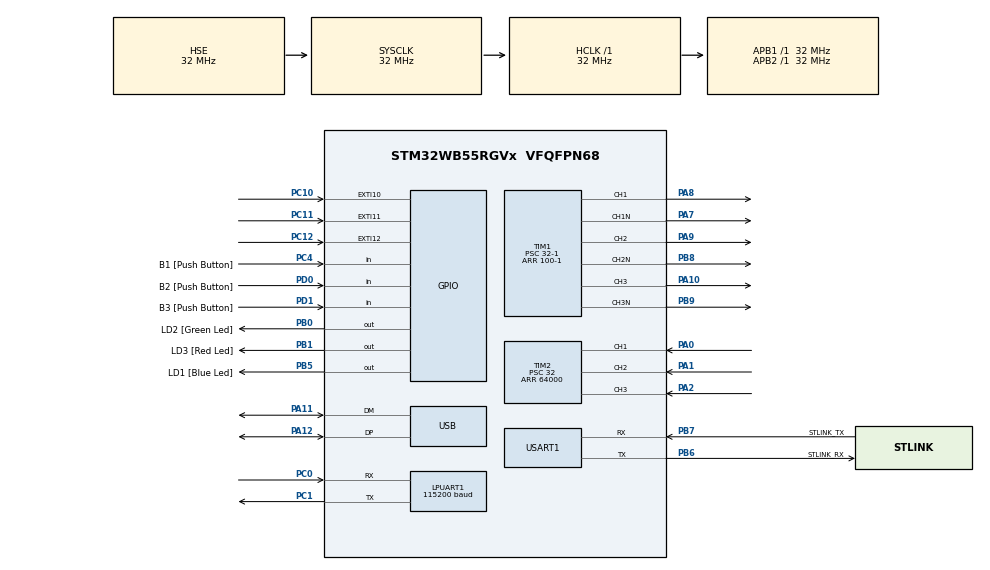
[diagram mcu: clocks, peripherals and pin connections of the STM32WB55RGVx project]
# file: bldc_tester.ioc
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Dma.Request0=TIM1_CH1
Dma.Request1=TIM1_CH2
Dma.Request2=TIM1_CH3
Dma.TIM1_CH1.0.Direction=DMA_PERIPH_TO_MEMORY
Dma.TIM1_CH1.0.EventEnable=DISABLE
Dma.TIM1_CH1.0.Instance=DMA1_Channel1
Dma.TIM1_CH1.0.MemDataAlignment=DMA_MDATAALIGN_HALFWORD
Dma.TIM1_CH1.0.MemInc=DMA_MINC_ENABLE
Dma.TIM1_CH1.0.Mode=DMA_NORMAL
Dma.TIM1_CH1.0.PeriphDataAlignment=DMA_PDATAALIGN_HALFWORD
Dma.TIM1_CH1.0.PeriphInc=DMA_PINC_DISABLE
Dma.TIM1_CH1.0.Polarity=HAL_DMAMUX_REQ_GEN_RISING
Dma.TIM1_CH1.0.Priority=DMA_PRIORITY_LOW
Dma.TIM1_CH1.0.RequestNumber=1
Dma.TIM1_CH1.0.SignalID=NONE
Dma.TIM1_CH1.0.SyncEnable=DISABLE
Dma.TIM1_CH1.0.SyncPolarity=HAL_DMAMUX_SYNC_NO_EVENT
Dma.TIM1_CH1.0.SyncRequestNumber=1
Dma.TIM1_CH1.0.SyncSignalID=NONE
Dma.TIM1_CH2.1.Direction=DMA_PERIPH_TO_MEMORY
Dma.TIM1_CH2.1.EventEnable=DISABLE
Dma.TIM1_CH2.1.Instance=DMA1_Channel2
Dma.TIM1_CH2.1.MemDataAlignment=DMA_MDATAALIGN_HALFWORD
Dma.TIM1_CH2.1.MemInc=DMA_MINC_ENABLE
Dma.TIM1_CH2.1.Mode=DMA_NORMAL
Dma.TIM1_CH2.1.PeriphDataAlignment=DMA_PDATAALIGN_HALFWORD
Dma.TIM1_CH2.1.PeriphInc=DMA_PINC_DISABLE
Dma.TIM1_CH2.1.Polarity=HAL_DMAMUX_REQ_GEN_RISING
Dma.TIM1_CH2.1.Priority=DMA_PRIORITY_LOW
Dma.TIM1_CH2.1.RequestNumber=1
Dma.TIM1_CH2.1.SignalID=NONE
Dma.TIM1_CH2.1.SyncEnable=DISABLE
Dma.TIM1_CH2.1.SyncPolarity=HAL_DMAMUX_SYNC_NO_EVENT
Dma.TIM1_CH2.1.SyncRequestNumber=1
Dma.TIM1_CH2.1.SyncSignalID=NONE
Dma.TIM1_CH3.2.Direction=DMA_PERIPH_TO_MEMORY
Dma.TIM1_CH3.2.EventEnable=DISABLE
Dma.TIM1_CH3.2.Instance=DMA1_Channel3
Dma.TIM1_CH3.2.MemDataAlignment=DMA_MDATAALIGN_HALFWORD
Dma.TIM1_CH3.2.MemInc=DMA_MINC_ENABLE
Dma.TIM1_CH3.2.Mode=DMA_NORMAL
Dma.TIM1_CH3.2.PeriphDataAlignment=DMA_PDATAALIGN_HALFWORD
Dma.TIM1_CH3.2.PeriphInc=DMA_PINC_DISABLE
Dma.TIM1_CH3.2.Polarity=HAL_DMAMUX_REQ_GEN_RISING
Dma.TIM1_CH3.2.Priority=DMA_PRIORITY_LOW
Dma.TIM1_CH3.2.RequestNumber=1
Dma.TIM1_CH3.2.SignalID=NONE
Dma.TIM1_CH3.2.SyncEnable=DISABLE
Dma.TIM1_CH3.2.SyncPolarity=HAL_DMAMUX_SYNC_NO_EVENT
Dma.TIM1_CH3.2.SyncRequestNumber=1
Dma.TIM1_CH3.2.SyncSignalID=NONE
LPUART1.BaudRate=115200
Mcu.Family=STM32WB
Mcu.Name=STM32WB55RGVx
Mcu.Package=VFQFPN68
NVIC.DMA1_Channel1_IRQn=true\:0\:0\:false\:false\:true\:false\:true\:true
NVIC.DMA1_Channel2_IRQn=true\:0\:0\:false\:false\:true\:false\:true\:true
NVIC.DMA1_Channel3_IRQn=true\:0\:0\:false\:false\:true\:false\:true\:true
NVIC.EXTI15_10_IRQn=true\:0\:0\:false\:false\:true\:true\:true\:true
NVIC.LPUART1_IRQn=true\:0\:0\:false\:false\:true\:true\:true\:true
NVIC.PriorityGroup=NVIC_PRIORITYGROUP_4
NVIC.TIM2_IRQn=true\:0\:0\:false\:false\:true\:true\:true\:true
NVIC.USART1_IRQn=true\:0\:0\:false\:false\:true\:true\:true\:true
OSC_IN.Mode=HSE-External-Oscillator
OSC_IN.Signal=RCC_OSC_IN
OSC_OUT.Mode=HSE-External-Oscillator
OSC_OUT.Signal=RCC_OSC_OUT
PA0.Signal=S_TIM2_CH1
PA1.Signal=S_TIM2_CH2
PA10.Signal=S_TIM1_CH3
PA11.Mode=Device
PA11.Signal=USB_DM
PA12.Mode=Device
PA12.Signal=USB_DP
PA13.GPIO_Label=JTMS
PA13.Mode=Trace_Asynchronous_SW
PA13.Signal=SYS_JTMS-SWDIO
PA14.GPIO_Label=JTCK
PA14.Mode=Trace_Asynchronous_SW
PA14.Signal=SYS_JTCK-SWCLK
PA2.Signal=S_TIM2_CH3
PA7.Mode=PWM Generation1 CH1 CH1N
PA7.Signal=TIM1_CH1N
PA8.Signal=S_TIM1_CH1
PA9.Signal=S_TIM1_CH2
PB0.GPIO_Label=LD2 [Green Led]
PB0.Signal=GPIO_Output
PB1.GPIO_Label=LD3 [Red Led]
PB1.Signal=GPIO_Output
PB3.GPIO_Label=JTDO
PB3.Mode=Trace_Asynchronous_SW
PB3.Signal=SYS_JTDO-SWO
PB5.GPIO_Label=LD1 [Blue Led]
PB5.Signal=GPIO_Output
PB6.GPIO_Label=STLINK_RX
PB6.GPIO_PuPd=GPIO_PULLUP
PB6.Mode=Asynchronous
PB6.Signal=USART1_TX
PB7.GPIO_Label=STLINK_TX
PB7.GPIO_PuPd=GPIO_PULLUP
PB7.Mode=Asynchronous
PB7.Signal=USART1_RX
PB8.Mode=PWM Generation2 CH2 CH2N
PB8.Signal=TIM1_CH2N
PB9.Mode=PWM Generation3 CH3 CH3N
PB9.Signal=TIM1_CH3N
PC0.Mode=Asynchronous
PC0.Signal=LPUART1_RX
PC1.Mode=Asynchronous
PC1.Signal=LPUART1_TX
PC10.GPIO_ModeDefaultEXTI=GPIO_MODE_IT_RISING_FALLING
PC10.Signal=GPXTI10
PC11.GPIO_ModeDefaultEXTI=GPIO_MODE_IT_RISING_FALLING
PC11.Signal=GPXTI11
PC12.GPIO_ModeDefaultEXTI=GPIO_MODE_IT_RISING_FALLING
PC12.Signal=GPXTI12
PC13.Mode=SYS_WakeUp1
PC13.Signal=SYS_WKUP2
PC14-OSC32_IN.Mode=LSE-External-Oscillator
PC14-OSC32_IN.Signal=RCC_OSC32_IN
PC15-OSC32_OUT.Mode=LSE-External-Oscillator
PC15-OSC32_OUT.Signal=RCC_OSC32_OUT
PC4.GPIO_Label=B1 [Push Button]
PC4.Signal=GPIO_Input
PD0.GPIO_Label=B2 [Push Button]
PD0.Signal=GPIO_Input
PD1.GPIO_Label=B3 [Push Button]
PD1.Signal=GPIO_Input
ProjectManager.HeapSize=0x400
ProjectManager.StackSize=0x800
ProjectManager.TargetToolchain=EWARM V8.32
RCC.ADCFreq_Value=48000000
RCC.AHBFreq_Value=32000000
RCC.APB1Freq_Value=32000000
RCC.APB1TimFreq_Value=32000000
RCC.APB2Freq_Value=32000000
RCC.APB2TimFreq_Value=32000000
RCC.APB3Freq_Value=16000000
RCC.CortexFreq_Value=32000000
RCC.HCLKFreq_Value=32000000
RCC.HSE_VALUE=32000000
RCC.HSI48_VALUE=48000000
RCC.HSI_VALUE=16000000
RCC.PLLN=32
RCC.PLLSAI1N=24
RCC.SMPSCLockSelectionVirtual=RCC_SMPSCLKSOURCE_HSI
RCC.SMPSCLockSelectionVirtualVirtual=RCC_SMPSCLKSOURCE_HSI
RCC.SMPSDivider=1
RCC.SYSCLKFreq_VALUE=32000000
RCC.SYSCLKSource=RCC_SYSCLKSOURCE_HSE
RCC.USBFreq_Value=48000000
RCC.VCOOutputFreq_Value=128000000
SH.S_TIM1_CH1.0=TIM1_CH1,PWM Generation1 CH1 CH1N
SH.S_TIM1_CH2.0=TIM1_CH2,PWM Generation2 CH2 CH2N
SH.S_TIM1_CH3.0=TIM1_CH3,PWM Generation3 CH3 CH3N
SH.S_TIM2_CH1.0=TIM2_CH1,Xored_Inputs_Hall_Sensor_Interface
SH.S_TIM2_CH2.0=TIM2_CH2,Xored_Inputs_Hall_Sensor_Interface
SH.S_TIM2_CH3.0=TIM2_CH3,Xored_Inputs_Hall_Sensor_Interface
TIM1.Channel-PWM\ Generation1\ CH1\ CH1N=TIM_CHANNEL_1
TIM1.Channel-PWM\ Generation2\ CH2\ CH2N=TIM_CHANNEL_2
TIM1.Channel-PWM\ Generation3\ CH3\ CH3N=TIM_CHANNEL_3
TIM1.DeadTime=127
TIM1.Period=100-1
TIM1.Prescaler=32-1
TIM2.Period=64000
TIM2.Prescaler=32
USART1.VirtualMode-Asynchronous=VM_ASYNC
USART1.WordLength=WORDLENGTH_7B
VP_TIM16_VS_ClockSourceINT.Mode=Enable_Timer
VP_TIM1_VS_ClockSourceINT.Mode=Internal
VP_TIM2_VS_ClockSourceINT.Mode=Internal
board=P-NUCLEO-WB55-NUCLEO

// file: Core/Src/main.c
/****************************************************************************************
* ALI SAHBAZ
*
*
* Gateway Firmware v1.0
*
* Date          : 22.11.2022
* By            : Ali Sahbaz
* e-mail        : ali_sahbaz@outlook.com
*/
#include "main.h"
#include "bldc_driver_user_interface.h"

unsigned char UART_Receive_Byte[2]={0,0};
unsigned char UART_Receive_Byte2[2]={0,0};

UART_HandleTypeDef hlpuart1;
UART_HandleTypeDef huart1;

TIM_HandleTypeDef htim1;
TIM_HandleTypeDef htim2;
TIM_HandleTypeDef htim16;
DMA_HandleTypeDef hdma_tim1_ch1;
DMA_HandleTypeDef hdma_tim1_ch2;
DMA_HandleTypeDef hdma_tim1_ch3;

PCD_HandleTypeDef hpcd_USB_FS;

void SystemClock_Config(void);
void PeriphCommonClock_Config(void);
static void MX_GPIO_Init(void);
static void MX_DMA_Init(void);
static void MX_TIM1_Init(void);
static void MX_TIM2_Init(void);
static void MX_TIM16_Init(void);
static void MX_USART1_UART_Init(void);
static void MX_USB_PCD_Init(void);
static void MX_LPUART1_UART_Init(void);

void main_systick(void){
  bldc_user_systick();
}

int main(void)
{
  HAL_Init();

  SystemClock_Config();

  PeriphCommonClock_Config();

  MX_GPIO_Init();
  MX_DMA_Init();
  MX_TIM1_Init();
  MX_TIM2_Init();
  MX_TIM16_Init();
  MX_USART1_UART_Init();
  MX_USB_PCD_Init();
  MX_LPUART1_UART_Init();

   /** APP INIT**/
  bldc_user_init();

  while (1)
  {
    /** APP **/
     bldc_user_loop();

  }
}

/********* HARDWARE ************************************************************/

void SystemClock_Config(void)
{
  RCC_OscInitTypeDef RCC_OscInitStruct = {0};
  RCC_ClkInitTypeDef RCC_ClkInitStruct = {0};

  /** Macro to configure the PLL multiplication factor
  */
  __HAL_RCC_PLL_PLLM_CONFIG(RCC_PLLM_DIV1);

  /** Macro to configure the PLL clock source
  */
  __HAL_RCC_PLL_PLLSOURCE_CONFIG(RCC_PLLSOURCE_MSI);

  /** Configure LSE Drive Capability
  */
  HAL_PWR_EnableBkUpAccess();
  __HAL_RCC_LSEDRIVE_CONFIG(RCC_LSEDRIVE_LOW);

  /** Configure the main internal regulator output voltage
  */
  __HAL_PWR_VOLTAGESCALING_CONFIG(PWR_REGULATOR_VOLTAGE_SCALE1);

  /** Initializes the RCC Oscillators according to the specified parameters
  * in the RCC_OscInitTypeDef structure.
  */
  RCC_OscInitStruct.OscillatorType = RCC_OSCILLATORTYPE_HSI|RCC_OSCILLATORTYPE_HSE
                              |RCC_OSCILLATORTYPE_LSE|RCC_OSCILLATORTYPE_MSI;
  RCC_OscInitStruct.HSEState = RCC_HSE_ON;
  RCC_OscInitStruct.LSEState = RCC_LSE_ON;
  RCC_OscInitStruct.HSIState = RCC_HSI_ON;
  RCC_OscInitStruct.MSIState = RCC_MSI_ON;
  RCC_OscInitStruct.HSICalibrationValue = RCC_HSICALIBRATION_DEFAULT;
  RCC_OscInitStruct.MSICalibrationValue = RCC_MSICALIBRATION_DEFAULT;
  RCC_OscInitStruct.MSIClockRange = RCC_MSIRANGE_6;
  RCC_OscInitStruct.PLL.PLLState = RCC_PLL_NONE;
  if (HAL_RCC_OscConfig(&RCC_OscInitStruct) != HAL_OK)
  {
    Error_Handler();
  }

  /** Configure the SYSCLKSource, HCLK, PCLK1 and PCLK2 clocks dividers
  */
  RCC_ClkInitStruct.ClockType = RCC_CLOCKTYPE_HCLK4|RCC_CLOCKTYPE_HCLK2
                              |RCC_CLOCKTYPE_HCLK|RCC_CLOCKTYPE_SYSCLK
                              |RCC_CLOCKTYPE_PCLK1|RCC_CLOCKTYPE_PCLK2;
  RCC_ClkInitStruct.SYSCLKSource = RCC_SYSCLKSOURCE_HSE;
  RCC_ClkInitStruct.AHBCLKDivider = RCC_SYSCLK_DIV1;
  RCC_ClkInitStruct.APB1CLKDivider = RCC_HCLK_DIV1;
  RCC_ClkInitStruct.APB2CLKDivider = RCC_HCLK_DIV1;
  RCC_ClkInitStruct.AHBCLK2Divider = RCC_SYSCLK_DIV1;
  RCC_ClkInitStruct.AHBCLK4Divider = RCC_SYSCLK_DIV1;

  if (HAL_RCC_ClockConfig(&RCC_ClkInitStruct, FLASH_LATENCY_1) != HAL_OK)
  {
    Error_Handler();
  }

  /** Enable MSI Auto calibration
  */
  HAL_RCCEx_EnableMSIPLLMode();
}

void PeriphCommonClock_Config(void)
{
  RCC_PeriphCLKInitTypeDef PeriphClkInitStruct = {0};

  /** Initializes the peripherals clock
  */
  PeriphClkInitStruct.PeriphClockSelection = RCC_PERIPHCLK_SMPS;
  PeriphClkInitStruct.SmpsClockSelection = RCC_SMPSCLKSOURCE_HSI;
  PeriphClkInitStruct.SmpsDivSelection = RCC_SMPSCLKDIV_RANGE0;

  if (HAL_RCCEx_PeriphCLKConfig(&PeriphClkInitStruct) != HAL_OK)
  {
    Error_Handler();
  }
}

static void MX_LPUART1_UART_Init(void)
{

  hlpuart1.Instance = LPUART1;
  hlpuart1.Init.BaudRate = 115200;
  hlpuart1.Init.WordLength = UART_WORDLENGTH_8B;
  hlpuart1.Init.StopBits = UART_STOPBITS_1;
  hlpuart1.Init.Parity = UART_PARITY_NONE;
  hlpuart1.Init.Mode = UART_MODE_TX_RX;
  hlpuart1.Init.HwFlowCtl = UART_HWCONTROL_NONE;
  hlpuart1.Init.OneBitSampling = UART_ONE_BIT_SAMPLE_DISABLE;
  hlpuart1.Init.ClockPrescaler = UART_PRESCALER_DIV1;
  hlpuart1.AdvancedInit.AdvFeatureInit = UART_ADVFEATURE_NO_INIT;
  hlpuart1.FifoMode = UART_FIFOMODE_DISABLE;
  if (HAL_UART_Init(&hlpuart1) != HAL_OK)
  {
    Error_Handler();
  }
  if (HAL_UARTEx_SetTxFifoThreshold(&hlpuart1, UART_TXFIFO_THRESHOLD_1_8) != HAL_OK)
  {
    Error_Handler();
  }
  if (HAL_UARTEx_SetRxFifoThreshold(&hlpuart1, UART_RXFIFO_THRESHOLD_1_8) != HAL_OK)
  {
    Error_Handler();
  }
  if (HAL_UARTEx_DisableFifoMode(&hlpuart1) != HAL_OK)
  {
    Error_Handler();
  }
  /* USER CODE BEGIN LPUART1_Init 2 */
HAL_UART_Receive_IT(&hlpuart1,(unsigned char*)UART_Receive_Byte2,1);
  /* USER CODE END LPUART1_Init 2 */

}

static void MX_USART1_UART_Init(void)
{

  huart1.Instance = USART1;
  huart1.Init.BaudRate = 115200;
  huart1.Init.WordLength = UART_WORDLENGTH_7B;
  huart1.Init.StopBits = UART_STOPBITS_1;
  huart1.Init.Parity = UART_PARITY_NONE;
  huart1.Init.Mode = UART_MODE_TX_RX;
  huart1.Init.HwFlowCtl = UART_HWCONTROL_NONE;
  huart1.Init.OverSampling = UART_OVERSAMPLING_16;
  huart1.Init.OneBitSampling = UART_ONE_BIT_SAMPLE_DISABLE;
  huart1.Init.ClockPrescaler = UART_PRESCALER_DIV1;
  huart1.AdvancedInit.AdvFeatureInit = UART_ADVFEATURE_NO_INIT;
  if (HAL_UART_Init(&huart1) != HAL_OK)
  {
    Error_Handler();
  }
  if (HAL_UARTEx_SetTxFifoThreshold(&huart1, UART_TXFIFO_THRESHOLD_1_8) != HAL_OK)
  {
    Error_Handler();
  }
  if (HAL_UARTEx_SetRxFifoThreshold(&huart1, UART_RXFIFO_THRESHOLD_1_8) != HAL_OK)
  {
    Error_Handler();
  }
  if (HAL_UARTEx_DisableFifoMode(&huart1) != HAL_OK)
  {
    Error_Handler();
  }
  /* USER CODE BEGIN USART1_Init 2 */
   HAL_UART_Receive_IT(&huart1,(unsigned char*)UART_Receive_Byte,1);
  /* USER CODE END USART1_Init 2 */

}

static void MX_TIM1_Init(void)
{

  TIM_ClockConfigTypeDef sClockSourceConfig = {0};
  TIM_MasterConfigTypeDef sMasterConfig = {0};
  TIM_OC_InitTypeDef sConfigOC = {0};
  TIM_BreakDeadTimeConfigTypeDef sBreakDeadTimeConfig = {0};

  htim1.Instance = TIM1;
  htim1.Init.Prescaler = 32-1;
  htim1.Init.CounterMode = TIM_COUNTERMODE_UP;
  htim1.Init.Period = 100-1;
  htim1.Init.ClockDivision = TIM_CLOCKDIVISION_DIV1;
  htim1.Init.RepetitionCounter = 0;
  htim1.Init.AutoReloadPreload = TIM_AUTORELOAD_PRELOAD_DISABLE;
  if (HAL_TIM_Base_Init(&htim1) != HAL_OK)
  {
    Error_Handler();
  }
  sClockSourceConfig.ClockSource = TIM_CLOCKSOURCE_INTERNAL;
  if (HAL_TIM_ConfigClockSource(&htim1, &sClockSourceConfig) != HAL_OK)
  {
    Error_Handler();
  }
  if (HAL_TIM_PWM_Init(&htim1) != HAL_OK)
  {
    Error_Handler();
  }
  sMasterConfig.MasterOutputTrigger = TIM_TRGO_RESET;
  sMasterConfig.MasterOutputTrigger2 = TIM_TRGO2_RESET;
  sMasterConfig.MasterSlaveMode = TIM_MASTERSLAVEMODE_DISABLE;
  if (HAL_TIMEx_MasterConfigSynchronization(&htim1, &sMasterConfig) != HAL_OK)
  {
    Error_Handler();
  }
  sConfigOC.OCMode = TIM_OCMODE_PWM1;
  sConfigOC.Pulse = 0;
  sConfigOC.OCPolarity = TIM_OCPOLARITY_HIGH;
  sConfigOC.OCNPolarity = TIM_OCNPOLARITY_HIGH;
  sConfigOC.OCFastMode = TIM_OCFAST_DISABLE;
  sConfigOC.OCIdleState = TIM_OCIDLESTATE_RESET;
  sConfigOC.OCNIdleState = TIM_OCNIDLESTATE_RESET;
  if (HAL_TIM_PWM_ConfigChannel(&htim1, &sConfigOC, TIM_CHANNEL_1) != HAL_OK)
  {
    Error_Handler();
  }
  if (HAL_TIM_PWM_ConfigChannel(&htim1, &sConfigOC, TIM_CHANNEL_2) != HAL_OK)
  {
    Error_Handler();
  }
  if (HAL_TIM_PWM_ConfigChannel(&htim1, &sConfigOC, TIM_CHANNEL_3) != HAL_OK)
  {
    Error_Handler();
  }
  sBreakDeadTimeConfig.OffStateRunMode = TIM_OSSR_DISABLE;
  sBreakDeadTimeConfig.OffStateIDLEMode = TIM_OSSI_DISABLE;
  sBreakDeadTimeConfig.LockLevel = TIM_LOCKLEVEL_OFF;
  sBreakDeadTimeConfig.DeadTime = 127;
  sBreakDeadTimeConfig.BreakState = TIM_BREAK_DISABLE;
  sBreakDeadTimeConfig.BreakPolarity = TIM_BREAKPOLARITY_HIGH;
  sBreakDeadTimeConfig.BreakFilter = 0;
  sBreakDeadTimeConfig.BreakAFMode = TIM_BREAK_AFMODE_INPUT;
  sBreakDeadTimeConfig.Break2State = TIM_BREAK2_DISABLE;
  sBreakDeadTimeConfig.Break2Polarity = TIM_BREAK2POLARITY_HIGH;
  sBreakDeadTimeConfig.Break2Filter = 0;
  sBreakDeadTimeConfig.Break2AFMode = TIM_BREAK_AFMODE_INPUT;
  sBreakDeadTimeConfig.AutomaticOutput = TIM_AUTOMATICOUTPUT_DISABLE;
  if (HAL_TIMEx_ConfigBreakDeadTime(&htim1, &sBreakDeadTimeConfig) != HAL_OK)
  {
    Error_Handler();
  }
  HAL_TIM_MspPostInit(&htim1);

}

static void MX_TIM2_Init(void)
{

  TIM_ClockConfigTypeDef sClockSourceConfig = {0};
  TIM_HallSensor_InitTypeDef sConfig = {0};
  TIM_MasterConfigTypeDef sMasterConfig = {0};

  htim2.Instance = TIM2;
  htim2.Init.Prescaler = 32;
  htim2.Init.CounterMode = TIM_COUNTERMODE_UP;
  htim2.Init.Period = 64000;
  htim2.Init.ClockDivision = TIM_CLOCKDIVISION_DIV1;
  htim2.Init.AutoReloadPreload = TIM_AUTORELOAD_PRELOAD_DISABLE;
  if (HAL_TIM_Base_Init(&htim2) != HAL_OK)
  {
    Error_Handler();
  }
  sClockSourceConfig.ClockSource = TIM_CLOCKSOURCE_INTERNAL;
  if (HAL_TIM_ConfigClockSource(&htim2, &sClockSourceConfig) != HAL_OK)
  {
    Error_Handler();
  }
  sConfig.IC1Polarity = TIM_ICPOLARITY_RISING;
  sConfig.IC1Prescaler = TIM_ICPSC_DIV1;
  sConfig.IC1Filter = 0;
  sConfig.Commutation_Delay = 0;
  if (HAL_TIMEx_HallSensor_Init(&htim2, &sConfig) != HAL_OK)
  {
    Error_Handler();
  }
  sMasterConfig.MasterOutputTrigger = TIM_TRGO_OC2REF;
  sMasterConfig.MasterSlaveMode = TIM_MASTERSLAVEMODE_DISABLE;
  if (HAL_TIMEx_MasterConfigSynchronization(&htim2, &sMasterConfig) != HAL_OK)
  {
    Error_Handler();
  }
  /* USER CODE BEGIN TIM2_Init 2 */
  HAL_TIM_Base_Start_IT(&htim2);
  //HAL_TIMEx_ConfigCommutEvent_IT(&htim2, TIM_TS_NONE, TIM_COMMUTATION_SOFTWARE);
  /* USER CODE END TIM2_Init 2 */

}

static void MX_TIM16_Init(void)
{

  htim16.Instance = TIM16;
  htim16.Init.Prescaler = 0;
  htim16.Init.CounterMode = TIM_COUNTERMODE_UP;
  htim16.Init.Period = 65535;
  htim16.Init.ClockDivision = TIM_CLOCKDIVISION_DIV1;
  htim16.Init.RepetitionCounter = 0;
  htim16.Init.AutoReloadPreload = TIM_AUTORELOAD_PRELOAD_DISABLE;
  if (HAL_TIM_Base_Init(&htim16) != HAL_OK)
  {
    Error_Handler();
  }

}

static void MX_USB_PCD_Init(void)
{

  hpcd_USB_FS.Instance = USB;
  hpcd_USB_FS.Init.dev_endpoints = 8;
  hpcd_USB_FS.Init.speed = PCD_SPEED_FULL;
  hpcd_USB_FS.Init.phy_itface = PCD_PHY_EMBEDDED;
  hpcd_USB_FS.Init.Sof_enable = DISABLE;
  hpcd_USB_FS.Init.low_power_enable = DISABLE;
  hpcd_USB_FS.Init.lpm_enable = DISABLE;
  hpcd_USB_FS.Init.battery_charging_enable = DISABLE;
  if (HAL_PCD_Init(&hpcd_USB_FS) != HAL_OK)
  {
    Error_Handler();
  }

}

static void MX_DMA_Init(void)
{

  /* DMA controller clock enable */
  __HAL_RCC_DMAMUX1_CLK_ENABLE();
  __HAL_RCC_DMA1_CLK_ENABLE();

  /* DMA interrupt init */
  /* DMA1_Channel1_IRQn interrupt configuration */
  HAL_NVIC_SetPriority(DMA1_Channel1_IRQn, 0, 0);
  HAL_NVIC_EnableIRQ(DMA1_Channel1_IRQn);
  /* DMA1_Channel2_IRQn interrupt configuration */
  HAL_NVIC_SetPriority(DMA1_Channel2_IRQn, 0, 0);
  HAL_NVIC_EnableIRQ(DMA1_Channel2_IRQn);
  /* DMA1_Channel3_IRQn interrupt configuration */
  HAL_NVIC_SetPriority(DMA1_Channel3_IRQn, 0, 0);
  HAL_NVIC_EnableIRQ(DMA1_Channel3_IRQn);

}

static void MX_GPIO_Init(void)
{
  GPIO_InitTypeDef GPIO_InitStruct = {0};

  /* GPIO Ports Clock Enable */
  __HAL_RCC_GPIOC_CLK_ENABLE();
  __HAL_RCC_GPIOB_CLK_ENABLE();
  __HAL_RCC_GPIOA_CLK_ENABLE();
  __HAL_RCC_GPIOD_CLK_ENABLE();

  /*Configure GPIO pin Output Level */
  HAL_GPIO_WritePin(GPIOB, LD2_Pin|LD3_Pin|LD1_Pin, GPIO_PIN_RESET);

  /*Configure GPIO pin : B1_Pin */
  GPIO_InitStruct.Pin = B1_Pin;
  GPIO_InitStruct.Mode = GPIO_MODE_INPUT;
  GPIO_InitStruct.Pull = GPIO_NOPULL;
  HAL_GPIO_Init(B1_GPIO_Port, &GPIO_InitStruct);

  /*Configure GPIO pins : LD2_Pin LD3_Pin LD1_Pin */
  GPIO_InitStruct.Pin = LD2_Pin|LD3_Pin|LD1_Pin;
  GPIO_InitStruct.Mode = GPIO_MODE_OUTPUT_PP;
  GPIO_InitStruct.Pull = GPIO_NOPULL;
  GPIO_InitStruct.Speed = GPIO_SPEED_FREQ_LOW;
  HAL_GPIO_Init(GPIOB, &GPIO_InitStruct);

  /*Configure GPIO pins : PC10 PC11 PC12 */
  GPIO_InitStruct.Pin = GPIO_PIN_10|GPIO_PIN_11|GPIO_PIN_12;
  GPIO_InitStruct.Mode = GPIO_MODE_IT_RISING_FALLING;
  GPIO_InitStruct.Pull = GPIO_NOPULL;
  HAL_GPIO_Init(GPIOC, &GPIO_InitStruct);

  /*Configure GPIO pins : B2_Pin B3_Pin */
  GPIO_InitStruct.Pin = B2_Pin|B3_Pin;
  GPIO_InitStruct.Mode = GPIO_MODE_INPUT;
  GPIO_InitStruct.Pull = GPIO_NOPULL;
  HAL_GPIO_Init(GPIOD, &GPIO_InitStruct);

  /* EXTI interrupt init*/
  HAL_NVIC_SetPriority(EXTI15_10_IRQn, 0, 0);
  HAL_NVIC_EnableIRQ(EXTI15_10_IRQn);

}

void Error_Handler(void)
{
  __disable_irq();
  while (1)
  {
  }
}
